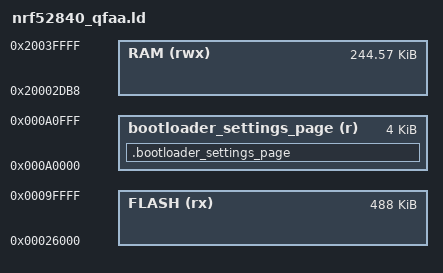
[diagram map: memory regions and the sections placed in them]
/* Linker script to configure memory regions. */

SEARCH_DIR(.)
GROUP(-lgcc -lc -lnosys)

MEMORY
{
  /* flash length is calculated using the flash origin of the bootloader_secure */
  /* last subtraction is to have some free flash for pin configuration settings and peer manager */
  FLASH (rx) : ORIGIN = 0x26000, LENGTH = 0xA0000 - 0x26000
  RAM (rwx) :  ORIGIN = 0x20002DB8, LENGTH = 0x3D248

  bootloader_settings_page (r) : ORIGIN = 0xA0000, LENGTH = 0x1000
}

SECTIONS
{
  .bootloader_settings_page(NOLOAD) :
  {
    PROVIDE(__start_bootloader_settings_page = .);
    KEEP(*(SORT(.bootloader_settings_page*)))
    PROVIDE(__stop_bootloader_settings_page = .);
  } > bootloader_settings_page
}

SECTIONS
{
  . = ALIGN(4);
  .mem_section_dummy_ram :
  {
  }
  .log_dynamic_data :
  {
    PROVIDE(__start_log_dynamic_data = .);
    KEEP(*(SORT(.log_dynamic_data*)))
    PROVIDE(__stop_log_dynamic_data = .);
  } > RAM
  .log_filter_data :
  {
    PROVIDE(__start_log_filter_data = .);
    KEEP(*(SORT(.log_filter_data*)))
    PROVIDE(__stop_log_filter_data = .);
  } > RAM
  .cli_sorted_cmd_ptrs :
  {
    PROVIDE(__start_cli_sorted_cmd_ptrs = .);
    KEEP(*(.cli_sorted_cmd_ptrs))
    PROVIDE(__stop_cli_sorted_cmd_ptrs = .);
  } > RAM
  .fs_data :
  {
    PROVIDE(__start_fs_data = .);
    KEEP(*(.fs_data))
    PROVIDE(__stop_fs_data = .);
  } > RAM
  
} INSERT AFTER .data;

SECTIONS
{
  .mem_section_dummy_rom :
  {
  }
  .svc_data :
  {
    PROVIDE(__start_svc_data = .);
    KEEP(*(.svc_data))
    PROVIDE(__stop_svc_data = .);
  } > FLASH
  .sdh_soc_observers :
  {
    PROVIDE(__start_sdh_soc_observers = .);
    KEEP(*(SORT(.sdh_soc_observers*)))
    PROVIDE(__stop_sdh_soc_observers = .);
  } > FLASH
  .pwr_mgmt_data :
  {
    PROVIDE(__start_pwr_mgmt_data = .);
    KEEP(*(SORT(.pwr_mgmt_data*)))
    PROVIDE(__stop_pwr_mgmt_data = .);
  } > FLASH
  .sdh_ble_observers :
  {
    PROVIDE(__start_sdh_ble_observers = .);
    KEEP(*(SORT(.sdh_ble_observers*)))
    PROVIDE(__stop_sdh_ble_observers = .);
  } > FLASH
  .log_const_data :
  {
    PROVIDE(__start_log_const_data = .);
    KEEP(*(SORT(.log_const_data*)))
    PROVIDE(__stop_log_const_data = .);
  } > FLASH
  .log_backends :
  {
    PROVIDE(__start_log_backends = .);
    KEEP(*(SORT(.log_backends*)))
    PROVIDE(__stop_log_backends = .);
  } > FLASH
  .sdh_req_observers :
  {
    PROVIDE(__start_sdh_req_observers = .);
    KEEP(*(SORT(.sdh_req_observers*)))
    PROVIDE(__stop_sdh_req_observers = .);
  } > FLASH
  .sdh_state_observers :
  {
    PROVIDE(__start_sdh_state_observers = .);
    KEEP(*(SORT(.sdh_state_observers*)))
    PROVIDE(__stop_sdh_state_observers = .);
  } > FLASH
  .sdh_stack_observers :
  {
    PROVIDE(__start_sdh_stack_observers = .);
    KEEP(*(SORT(.sdh_stack_observers*)))
    PROVIDE(__stop_sdh_stack_observers = .);
  } > FLASH 
  .nrf_balloc :
  {
    PROVIDE(__start_nrf_balloc = .);
    KEEP(*(.nrf_balloc))
    PROVIDE(__stop_nrf_balloc = .);
  } > FLASH
  .nrf_queue :
  {
    PROVIDE(__start_nrf_queue = .);
    KEEP(*(.nrf_queue))
    PROVIDE(__stop_nrf_queue = .);
  } > FLASH
  .cli_command :
  {
    PROVIDE(__start_cli_command = .);
    KEEP(*(.cli_command))
    PROVIDE(__stop_cli_command = .);
  } > FLASH
  .crypto_data :
  {
    PROVIDE(__start_crypto_data = .);
    KEEP(*(SORT(.crypto_data*)))
    PROVIDE(__stop_crypto_data = .);
  } > FLASH
} INSERT AFTER .text

INCLUDE "nrf_common.ld"
